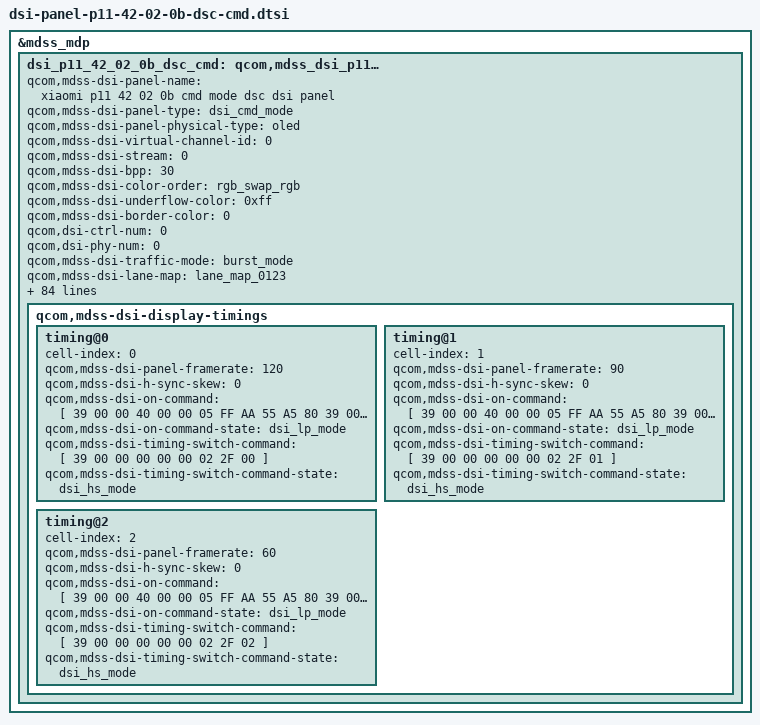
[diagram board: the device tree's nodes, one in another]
&mdss_mdp {
	dsi_p11_42_02_0b_dsc_cmd: qcom,mdss_dsi_p11_42_02_0b_dsc_cmd {
		qcom,mdss-dsi-panel-name = "xiaomi p11 42 02 0b cmd mode dsc dsi panel";
		qcom,mdss-dsi-panel-type = "dsi_cmd_mode";
		qcom,mdss-dsi-panel-physical-type = "oled";
		qcom,mdss-dsi-virtual-channel-id = <0>;
		qcom,mdss-dsi-stream = <0>;
		qcom,mdss-dsi-bpp = <30>;
		qcom,mdss-dsi-color-order = "rgb_swap_rgb";
		qcom,mdss-dsi-underflow-color = <0xff>;
		qcom,mdss-dsi-border-color = <0>;
		qcom,dsi-ctrl-num = <0>;
		qcom,dsi-phy-num = <0>;
		qcom,mdss-dsi-traffic-mode = "burst_mode";
		qcom,mdss-dsi-lane-map = "lane_map_0123";
		qcom,mdss-dsi-bllp-eof-power-mode;
		qcom,mdss-dsi-bllp-power-mode;
		qcom,mdss-dsi-lane-0-state;
		qcom,mdss-dsi-lane-1-state;
		qcom,mdss-dsi-lane-2-state;
		qcom,mdss-dsi-lane-3-state;
		qcom,mdss-dsi-dma-trigger = "trigger_sw";
		qcom,mdss-dsi-mdp-trigger = "none";
		qcom,mdss-dsi-reset-sequence =<1 1>, <0 1>, <1 10>;
		qcom,mdss-pan-physical-width-dimension = <701>;
		qcom,mdss-pan-physical-height-dimension = <1521>;
		qcom,mdss-dsi-te-pin-select = <1>;
		qcom,mdss-dsi-wr-mem-start = <0x2c>;
		qcom,mdss-dsi-wr-mem-continue = <0x3c>;
		qcom,mdss-dsi-te-dcs-command = <1>;
		qcom,mdss-dsi-te-check-enable;
		qcom,mdss-dsi-te-using-te-pin;
		qcom,mdss-dsi-tx-eot-append;
		qcom,mdss-dsi-lp11-init;
		qcom,mdss-dsi-bl-inverted-dbv;
		qcom,mdss-dsi-panel-dimming-enabled;
		qcom,bl-update-flag = "delay_until_first_frame";
		qcom,mdss-dsi-panel-hdr-enabled;
		qcom,mdss-dsi-panel-hdr-color-primaries = <14500 15500 32000
			17000 15500 30000 8000 3000>;
		qcom,mdss-dsi-panel-peak-brightness = <32000000>;
		qcom,mdss-dsi-panel-blackness-level = <3230>;
		qcom,mdss-dsi-dma-schedule-line = <1>;
		qcom,mdss-dsi-dma-schedule-window = <50>;
		mi,panel-id = <0x00503131 0x5042020B>;
		mi,panel-on-dimming-delay = <120>;

		/* IRQF_ONESHOT | IRQF_TRIGGER_LOW */
		mi,esd-err-irq-gpio = <&tlmm 87 0x2004>;
		mi,esd-err-irq-gpio-flag = <0x2004>;

		mi,mdss-dsi-panel-wp-read-command = [06 01 00 01 00 00 01 D7];
		mi,mdss-dsi-panel-wp-read-command-state = "dsi_hs_mode";
		mi,mdss-dsi-panel-wp-read-pre-tx-command = [39 00 00 00 00 00 06 F0 55 AA 52 08 01];
		mi,mdss-dsi-panel-wp-read-pre-tx-command-state = "dsi_hs_mode";
		mi,mdss-dsi-panel-wp-read-length = <8>;

		mi,mdss-dsi-panel-cell-id-read-command = [06 01 00 01 00 00 01 AC];
		mi,mdss-dsi-panel-cell-id-read-command-state = "dsi_hs_mode";
		mi,mdss-dsi-panel-cell-id-read-length = <14>;
		mi,max-brightness-clone = <16383>;
		mi,mdss-dsi-fac-bl-max-level = <6750>;
		mi,mdss-fac-brightness-max-level = <6750>;
		mi,flatmode-status-check-enabled;
		mi,mdss-dsi-panel-flatmode-status-command = [
				06 01 00 01 00 00 01 5F
		];
		mi,mdss-dsi-panel-flatmode-status-command-state = "dsi_hs_mode";
		mi,mdss-dsi-panel-flatmode-status-read-length = <1>;
		mi,mdss-dsi-panel-flatmode-on-status-value = <0x00>;

		mi,doze-hbm-dbv-level = <609>;
		mi,doze-lbm-dbv-level = <46>;
		mi,ddic-round-corner-enabled;
		qcom,mdss-disable-cesta-hw-sleep;

		qcom,mdss-dsi-display-timings {
			timing@0 {
				#include "dsi-panel-p11-42-02-0b-dsc-cmd-common.dtsi"
				cell-index = <0>;
				qcom,mdss-dsi-panel-framerate = <120>;
				qcom,mdss-dsi-h-sync-skew = <0>;

				qcom,mdss-dsi-on-command = [
					39 00 00 40 00 00 05 FF AA 55 A5 80
					39 00 00 40 00 00 02 6F 08
					39 00 00 40 00 00 08 F6 70 07 70 70 70 70 70
					39 00 00 40 00 00 05 FF AA 55 A5 80
					39 00 00 40 00 00 02 6F 21
					39 00 00 40 00 00 02 F4 08
					39 00 00 40 00 00 05 FF AA 55 A5 80
					39 00 00 40 00 00 02 6F 20
					39 00 00 40 00 00 02 F4 C0
					39 00 00 40 00 00 05 FF AA 55 A5 80
					39 00 00 40 00 00 02 6F 01
					39 00 00 40 00 00 02 F4 95
					39 00 00 40 00 00 02 6F 03
					39 00 00 40 00 00 02 F4 10
					39 00 00 40 00 00 05 FF AA 55 A5 80
					39 00 00 40 00 00 02 6F 13
					39 00 00 40 00 00 03 F9 FF FF
					39 00 00 40 00 00 05 FF AA 55 A5 80
					39 00 00 40 00 00 02 6F 47
					39 00 00 40 00 00 02 F2 25
					39 00 00 40 00 00 02 6F 21
					39 00 00 40 00 00 02 F8 04
					39 00 00 40 00 00 02 6F 05
					39 00 00 40 00 00 02 F8 04
					39 00 00 40 00 00 02 17 30
					39 00 00 40 00 00 02 26 00
					39 00 00 40 00 00 02 2F 00
					39 00 00 40 00 00 05 2A 00 00 04 83
					39 00 00 40 00 00 05 2B 00 00 09 CD
					39 00 00 40 00 00 02 35 00
					39 00 00 40 00 00 03 51 00 00
					39 00 00 40 00 00 02 6F 04
					39 00 00 40 00 00 03 51 00 00
					39 00 00 40 00 00 02 53 20
					39 00 00 40 00 00 03 5A 01 01
					39 00 00 40 00 00 02 90 03
					39 00 00 40 00 00 02 6F 01
					39 00 00 40 00 00 02 90 43
					39 00 00 40 00 00 13 91 AB 28 00 0A C2 00 02 22 00 D7 00 08 0A AB 09 8D 11 00
					39 00 00 00 78 00 01 11
					39 00 00 00 00 00 01 29
		          ];
				qcom,mdss-dsi-on-command-state = "dsi_lp_mode";
				qcom,mdss-dsi-timing-switch-command = [
					//120hz
					39 00 00 00 00 00 02 2F 00
				];
				qcom,mdss-dsi-timing-switch-command-state = "dsi_hs_mode";
			};
			timing@1 {
				#include "dsi-panel-p11-42-02-0b-dsc-cmd-common.dtsi"
				cell-index = <1>;
				qcom,mdss-dsi-panel-framerate = <90>;
				qcom,mdss-dsi-h-sync-skew = <0>;
				qcom,mdss-dsi-on-command = [
					39 00 00 40 00 00 05 FF AA 55 A5 80
					39 00 00 40 00 00 02 6F 08
					39 00 00 40 00 00 08 F6 70 07 70 70 70 70 70
					39 00 00 40 00 00 05 FF AA 55 A5 80
					39 00 00 40 00 00 02 6F 21
					39 00 00 40 00 00 02 F4 08
					39 00 00 40 00 00 05 FF AA 55 A5 80
					39 00 00 40 00 00 02 6F 20
					39 00 00 40 00 00 02 F4 C0
					39 00 00 40 00 00 05 FF AA 55 A5 80
					39 00 00 40 00 00 02 6F 01
					39 00 00 40 00 00 02 F4 95
					39 00 00 40 00 00 02 6F 03
					39 00 00 40 00 00 02 F4 10
					39 00 00 40 00 00 05 FF AA 55 A5 80
					39 00 00 40 00 00 02 6F 13
					39 00 00 40 00 00 03 F9 FF FF
					39 00 00 40 00 00 05 FF AA 55 A5 80
					39 00 00 40 00 00 02 6F 47
					39 00 00 40 00 00 02 F2 25
					39 00 00 40 00 00 02 6F 21
					39 00 00 40 00 00 02 F8 04
					39 00 00 40 00 00 02 6F 05
					39 00 00 40 00 00 02 F8 04
					39 00 00 40 00 00 02 17 30
					39 00 00 40 00 00 02 26 00
					39 00 00 40 00 00 02 2F 01
					39 00 00 40 00 00 05 2A 00 00 04 83
					39 00 00 40 00 00 05 2B 00 00 09 CD
					39 00 00 40 00 00 02 35 00
					39 00 00 40 00 00 03 51 00 00
					39 00 00 40 00 00 02 6F 04
					39 00 00 40 00 00 03 51 00 00
					39 00 00 40 00 00 02 53 20
					39 00 00 40 00 00 03 5A 01 01
					39 00 00 40 00 00 02 90 03
					39 00 00 40 00 00 02 6F 01
					39 00 00 40 00 00 02 90 43
					39 00 00 40 00 00 13 91 AB 28 00 0A C2 00 02 22 00 D7 00 08 0A AB 09 8D 11 00
					39 00 00 00 78 00 01 11
					39 00 00 00 00 00 01 29
		        ];
				qcom,mdss-dsi-on-command-state = "dsi_lp_mode";
                 qcom,mdss-dsi-timing-switch-command = [
					//90hz
					39 00 00 00 00 00 02 2F 01
				];
				qcom,mdss-dsi-timing-switch-command-state = "dsi_hs_mode";
			};
			timing@2 {
				#include "dsi-panel-p11-42-02-0b-dsc-cmd-common.dtsi"
				cell-index = <2>;
				qcom,mdss-dsi-panel-framerate = <60>;
				qcom,mdss-dsi-h-sync-skew = <0>;
				qcom,mdss-dsi-on-command = [
					39 00 00 40 00 00 05 FF AA 55 A5 80
					39 00 00 40 00 00 02 6F 08
					39 00 00 40 00 00 08 F6 70 07 70 70 70 70 70
					39 00 00 40 00 00 05 FF AA 55 A5 80
					39 00 00 40 00 00 02 6F 21
					39 00 00 40 00 00 02 F4 08
					39 00 00 40 00 00 05 FF AA 55 A5 80
					39 00 00 40 00 00 02 6F 20
					39 00 00 40 00 00 02 F4 C0
					39 00 00 40 00 00 05 FF AA 55 A5 80
					39 00 00 40 00 00 02 6F 01
					39 00 00 40 00 00 02 F4 95
					39 00 00 40 00 00 02 6F 03
					39 00 00 40 00 00 02 F4 10
					39 00 00 40 00 00 05 FF AA 55 A5 80
					39 00 00 40 00 00 02 6F 13
					39 00 00 40 00 00 03 F9 FF FF
					39 00 00 40 00 00 05 FF AA 55 A5 80
					39 00 00 40 00 00 02 6F 47
					39 00 00 40 00 00 02 F2 25
					39 00 00 40 00 00 02 6F 21
					39 00 00 40 00 00 02 F8 04
					39 00 00 40 00 00 02 6F 05
					39 00 00 40 00 00 02 F8 04
					39 00 00 40 00 00 02 17 30
					39 00 00 40 00 00 02 26 00
					39 00 00 40 00 00 02 2F 02
					39 00 00 40 00 00 05 2A 00 00 04 83
					39 00 00 40 00 00 05 2B 00 00 09 CD
					39 00 00 40 00 00 02 35 00
					39 00 00 40 00 00 03 51 00 00
					39 00 00 40 00 00 02 6F 04
					39 00 00 40 00 00 03 51 00 00
					39 00 00 40 00 00 02 53 20
					39 00 00 40 00 00 03 5A 01 01
					39 00 00 40 00 00 02 90 03
					39 00 00 40 00 00 02 6F 01
					39 00 00 40 00 00 02 90 43
					39 00 00 40 00 00 13 91 AB 28 00 0A C2 00 02 22 00 D7 00 08 0A AB 09 8D 11 00
					39 00 00 00 78 00 01 11
					39 00 00 00 00 00 01 29
		        ];
				qcom,mdss-dsi-on-command-state = "dsi_lp_mode";
                 qcom,mdss-dsi-timing-switch-command = [
					//60hz
					39 00 00 00 00 00 02 2F 02
				];
				qcom,mdss-dsi-timing-switch-command-state = "dsi_hs_mode";
			};
		};
	};
};

&dsi_p11_42_02_0b_dsc_cmd {
	qcom,panel-supply-entries = <&dsi_panel_pwr_supply_p11>;
	qcom,mdss-dsi-bl-pmic-control-type = "bl_ctrl_dcs";
	qcom,mdss-dsi-bl-min-level = <15>;
	qcom,mdss-dsi-bl-max-level = <16383>;
	qcom,bl-dsc-cmd-state = "dsi_hs_mode";
	qcom,mdss-brightness-max-level = <16383>;
	qcom,mdss-brightness-init-level = <614>;
	qcom,platform-reset-gpio = <&tlmm 98 0>;
	mi,panel-build-id-read-needed;
	mi,panel-build-id-read-length = <1>;
	mi,mdss-dsi-panel-build-id-read-command = [06 01 00 01 00 00 01 DA];
	mi,mdss-dsi-panel-build-id-read-command-state = "dsi_hs_mode";

	qcom,mdss-dsi-panel-vsync-delay;
	qcom,ulps-enabled;
	qcom,dsi-select-clocks = "pll_byte_clk0", "pll_dsi_clk0";
	qcom,mdss-dsi-clk-strength = <0x88>;
};
